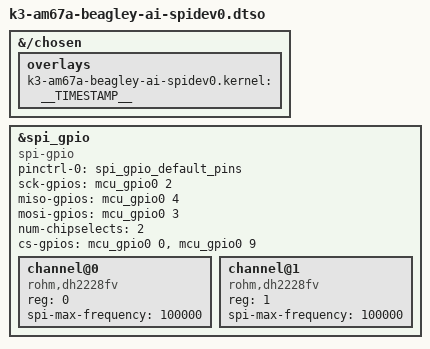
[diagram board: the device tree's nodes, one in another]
// SPDX-License-Identifier: GPL-2.0
/*
 * DT Overlay for spidev0.0 & spidev0.1 on BeagleY-AI board.
 *
 * Copyright (C) 2023 Texas Instruments Incorporated - https://www.ti.com/
 *
 */

/dts-v1/;
/plugin/;

#include <dt-bindings/gpio/gpio.h>

/*
 * Helper to show loaded overlays under: /proc/device-tree/chosen/overlays/
 */
&{/chosen} {
	overlays {
		k3-am67a-beagley-ai-spidev0.kernel = __TIMESTAMP__;
	};
};

&spi_gpio {
	compatible = "spi-gpio";
	#address-cells = <0x1>;
	#size-cells = <0x0>;
	pinctrl-names = "default";
	pinctrl-0 = <&spi_gpio_default_pins>;

	sck-gpios = <&mcu_gpio0 2 GPIO_ACTIVE_HIGH>;
	miso-gpios = <&mcu_gpio0 4 GPIO_ACTIVE_HIGH>;
	mosi-gpios = <&mcu_gpio0 3 GPIO_ACTIVE_HIGH>;

	num-chipselects = <2>;
	cs-gpios = <
		&mcu_gpio0 0 GPIO_ACTIVE_HIGH
		&mcu_gpio0 9 GPIO_ACTIVE_HIGH
	>;

	status = "okay";

	channel@0 {
		compatible = "rohm,dh2228fv";

		reg = <0>;
		spi-max-frequency = <100000>;
	};

	channel@1 {
		compatible = "rohm,dh2228fv";

		reg = <1>;
		spi-max-frequency = <100000>;
	};
};
